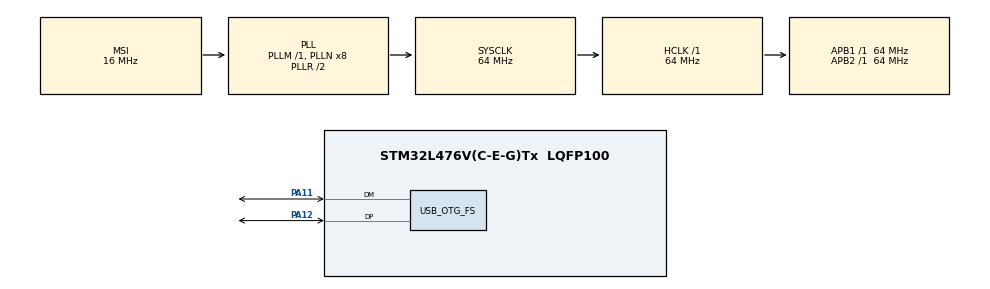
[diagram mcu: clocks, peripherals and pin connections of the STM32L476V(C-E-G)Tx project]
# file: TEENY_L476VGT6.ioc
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FREERTOS.Tasks01=defaultTask,0,128,StartDefaultTask,Default,NULL,Dynamic,NULL,NULL;myTask02,-3,128,StartTask02,Default,NULL,Dynamic,NULL,NULL;myTask03,-3,128,StartTask03,Default,NULL,Dynamic,NULL,NULL;myTask04,-3,128,StartTask04,Default,NULL,Dynamic,NULL,NULL;myTask05,-3,128,StartTask05,Default,NULL,Dynamic,NULL,NULL;myTask06,-3,128,StartTask06,Default,NULL,Dynamic,NULL,NULL
FREERTOS.configTOTAL_HEAP_SIZE=20480
Mcu.Family=STM32L4
Mcu.Name=STM32L476V(C-E-G)Tx
Mcu.Package=LQFP100
NVIC.PriorityGroup=NVIC_PRIORITYGROUP_4
NVIC.TIM1_UP_TIM16_IRQn=true\:15\:0\:false\:false\:true\:false\:false\:true\:true
NVIC.TimeBase=TIM1_UP_TIM16_IRQn
NVIC.TimeBaseIP=TIM1
PA11.Mode=Device_Only
PA11.Signal=USB_OTG_FS_DM
PA12.Mode=Device_Only
PA12.Signal=USB_OTG_FS_DP
PA13\ (JTMS-SWDIO).Mode=Serial_Wire
PA13\ (JTMS-SWDIO).Signal=SYS_JTMS-SWDIO
PA14\ (JTCK-SWCLK).Mode=Serial_Wire
PA14\ (JTCK-SWCLK).Signal=SYS_JTCK-SWCLK
ProjectManager.HeapSize=0x2000
ProjectManager.StackSize=0x4000
ProjectManager.TargetToolchain=MDK-ARM V5.32
RCC.ADCFreq_Value=96000000
RCC.AHBFreq_Value=64000000
RCC.APB1Freq_Value=64000000
RCC.APB1TimFreq_Value=64000000
RCC.APB2Freq_Value=64000000
RCC.APB2TimFreq_Value=64000000
RCC.CortexFreq_Value=64000000
RCC.HCLKFreq_Value=64000000
RCC.HSE_VALUE=8000000
RCC.HSI_VALUE=16000000
RCC.LSE_VALUE=32768
RCC.MSIClockRange=RCC_MSIRANGE_8
RCC.MSI_VALUE=16000000
RCC.PLLQ=RCC_PLLQ_DIV4
RCC.PLLSAI1N=12
RCC.PLLSAI1Q=RCC_PLLQ_DIV4
RCC.SYSCLKFreq_VALUE=64000000
RCC.SYSCLKSource=RCC_SYSCLKSOURCE_PLLCLK
RCC.USBFreq_Value=48000000
RCC.VCOOutputFreq_Value=128000000
USB_OTG_FS.Sof_enable=DISABLE
USB_OTG_FS.VirtualMode=Device_Only
USB_OTG_FS.low_power_enable=DISABLE
USB_OTG_FS.lpm_enable=ENABLE
VP_FREERTOS_VS_CMSIS_V1.Mode=CMSIS_V1
VP_SYS_VS_tim1.Mode=TIM1
board=custom

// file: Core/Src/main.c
/* USER CODE BEGIN Header */
/**
  ******************************************************************************
  * @file           : main.c
  * @brief          : Main program body
  ******************************************************************************
  * @attention
  *
  * Copyright (c) 2022 STMicroelectronics.
  * All rights reserved.
  *
  * This software is licensed under terms that can be found in the LICENSE file
  * in the root directory of this software component.
  * If no LICENSE file comes with this software, it is provided AS-IS.
  *
  ******************************************************************************
  */
/* USER CODE END Header */
#include "main.h"
#include "cmsis_os.h"
#include "usb_otg.h"
#include "gpio.h"

void SystemClock_Config(void);
void MX_FREERTOS_Init(void);
/* USER CODE BEGIN PFP */
extern int l476_usb_test(void);
/* USER CODE END PFP */

int main(void)
{

  /* MCU Configuration--------------------------------------------------------*/

  /* Reset of all peripherals, Initializes the Flash interface and the Systick. */
  HAL_Init();

  /* Configure the system clock */
  SystemClock_Config();

  /* USER CODE BEGIN SysInit */
#if 0
  /* USER CODE END SysInit */

  /* Initialize all configured peripherals */
  MX_GPIO_Init();
  MX_USB_OTG_FS_PCD_Init();
  /* USER CODE BEGIN 2 */
#endif
  MX_GPIO_Init();
//  MX_USB_OTG_FS_PCD_Init();
//	l476_usb_test();
  /* USER CODE END 2 */

  /* Call init function for freertos objects (in freertos.c) */
  MX_FREERTOS_Init();

  /* Start scheduler */
  osKernelStart();

  /* We should never get here as control is now taken by the scheduler */
  /* Infinite loop */
  while (1)
  {

  }
}

void SystemClock_Config(void)
{
  RCC_OscInitTypeDef RCC_OscInitStruct = {0};
  RCC_ClkInitTypeDef RCC_ClkInitStruct = {0};

  /** Configure the main internal regulator output voltage
  */
  if (HAL_PWREx_ControlVoltageScaling(PWR_REGULATOR_VOLTAGE_SCALE1) != HAL_OK)
  {
    Error_Handler();
  }

  /** Initializes the RCC Oscillators according to the specified parameters
  * in the RCC_OscInitTypeDef structure.
  */
  RCC_OscInitStruct.OscillatorType = RCC_OSCILLATORTYPE_MSI;
  RCC_OscInitStruct.MSIState = RCC_MSI_ON;
  RCC_OscInitStruct.MSICalibrationValue = 0;
  RCC_OscInitStruct.MSIClockRange = RCC_MSIRANGE_8;
  RCC_OscInitStruct.PLL.PLLState = RCC_PLL_ON;
  RCC_OscInitStruct.PLL.PLLSource = RCC_PLLSOURCE_MSI;
  RCC_OscInitStruct.PLL.PLLM = 1;
  RCC_OscInitStruct.PLL.PLLN = 8;
  RCC_OscInitStruct.PLL.PLLP = RCC_PLLP_DIV7;
  RCC_OscInitStruct.PLL.PLLQ = RCC_PLLQ_DIV4;
  RCC_OscInitStruct.PLL.PLLR = RCC_PLLR_DIV2;
  if (HAL_RCC_OscConfig(&RCC_OscInitStruct) != HAL_OK)
  {
    Error_Handler();
  }

  /** Initializes the CPU, AHB and APB buses clocks
  */
  RCC_ClkInitStruct.ClockType = RCC_CLOCKTYPE_HCLK|RCC_CLOCKTYPE_SYSCLK
                              |RCC_CLOCKTYPE_PCLK1|RCC_CLOCKTYPE_PCLK2;
  RCC_ClkInitStruct.SYSCLKSource = RCC_SYSCLKSOURCE_PLLCLK;
  RCC_ClkInitStruct.AHBCLKDivider = RCC_SYSCLK_DIV1;
  RCC_ClkInitStruct.APB1CLKDivider = RCC_HCLK_DIV1;
  RCC_ClkInitStruct.APB2CLKDivider = RCC_HCLK_DIV1;

  if (HAL_RCC_ClockConfig(&RCC_ClkInitStruct, FLASH_LATENCY_3) != HAL_OK)
  {
    Error_Handler();
  }
}

void HAL_TIM_PeriodElapsedCallback(TIM_HandleTypeDef *htim)
{
  if (htim->Instance == TIM1) {
    HAL_IncTick();
  }
}

void Error_Handler(void)
{
  __disable_irq();
  while (1)
  {
  }
}
